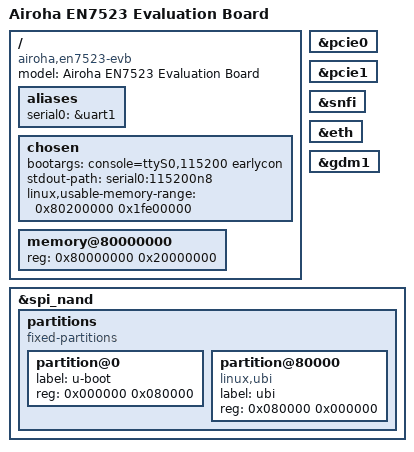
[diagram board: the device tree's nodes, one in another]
// SPDX-License-Identifier: (GPL-2.0-only OR BSD-2-Clause)
/dts-v1/;

#include "en7523.dtsi"

/ {
	model = "Airoha EN7523 Evaluation Board";
	compatible = "airoha,en7523-evb", "airoha,en7523";

	aliases {
		serial0 = &uart1;
	};

	chosen {
		bootargs = "console=ttyS0,115200 earlycon";
		stdout-path = "serial0:115200n8";
		linux,usable-memory-range = <0x80200000 0x1fe00000>;
	};

	memory@80000000 {
		device_type = "memory";
		reg = <0x80000000 0x20000000>;
	};
};

&pcie0 {
	status = "okay";
};

&pcie1 {
	status = "okay";
};

&snfi {
	status = "okay";
};

&eth {
	status = "okay";
};

&gdm1 {
	status = "okay";
};

&spi_nand {
	partitions {
		compatible = "fixed-partitions";
		#address-cells = <1>;
		#size-cells = <1>;

		partition@0 {
			label = "u-boot";
			reg = <0x000000 0x080000>;
		};

		partition@80000 {
			label = "ubi";
			compatible = "linux,ubi";
			reg = <0x080000 0x000000>;
		};
	};
};
